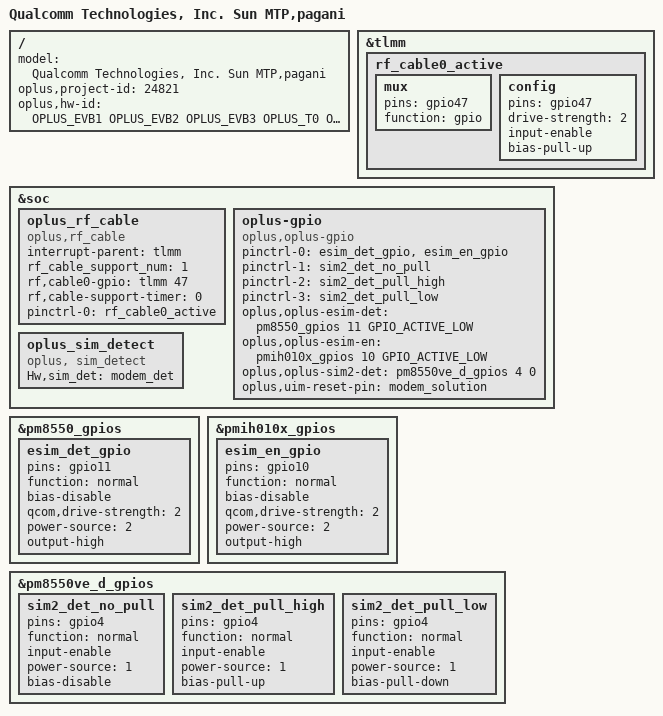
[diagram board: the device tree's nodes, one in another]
/dts-v1/;
/plugin/;
#include <dt-bindings/oplus/hw-id.h>
#include "../qcom/sun-mtp-v8-overlay.dts"
#include "sun_overlay_common.dtsi"
#include "oplus_nfc/pagani_nfc.dtsi"
#include "pagani_overlay_common.dtsi"
#include "oplus_misc/oplus-misc-24821.dtsi"
#include "oplus_uff/oplus-uff-24821.dtsi"
#include "tp/pagani-oplus-tp-24821.dtsi"
#include "oplus_chg/oplus-chg-24821.dtsi"
#include "sensor/pagani-sensor-24821-24875.dtsi"
#include "mm/pagani-24821-sun-mm.dtsi"

/ {
    model = "Qualcomm Technologies, Inc. Sun MTP,pagani";

    oplus,project-id = <24821>;
    oplus,hw-id = <OPLUS_EVB1 OPLUS_EVB2 OPLUS_EVB3 OPLUS_T0 OPLUS_T1 OPLUS_EVT1 OPLUS_EVT2 OPLUS_DVT1 OPLUS_DVT2 OPLUS_PVT1>;
};

&tlmm {
    //#ifdef OPLUS_FEATURE_RF_CABLE_DETECT
    rf_cable0_active: rf_cable0_active {
        mux {
            pins = "gpio47";
            function = "gpio";
        };
        config {
            pins = "gpio47";
            drive-strength = <2>;
            input-enable;
            bias-pull-up;
        };
    };
    //#endif /* OPLUS_FEATURE_RF_CABLE_DETECT */
};

&soc {
    //#ifdef OPLUS_FEATURE_RF_CABLE_DETECT
    oplus_rf_cable {
        compatible = "oplus,rf_cable";
        interrupt-parent = <&tlmm>;
        rf_cable_support_num = <1>;
        rf,cable0-gpio = <&tlmm 47 0>;
        rf,cable-support-timer = <0>;
        pinctrl-names = "rf_cable_active";
        pinctrl-0 = <&rf_cable0_active>;
    };
    //#endif /* OPLUS_FEATURE_RF_CABLE_DETECT */
    //#ifdef OPLUS_FEATURE_ESIM
    oplus-gpio {
        compatible = "oplus,oplus-gpio";
        pinctrl-names = "oplus_esim", "sim2_det_no_pull", "sim2_det_pull_high", "sim2_det_pull_low";
        pinctrl-0 = <&esim_det_gpio &esim_en_gpio>;
        pinctrl-1 = <&sim2_det_no_pull>;
        pinctrl-2 = <&sim2_det_pull_high>;
        pinctrl-3 = <&sim2_det_pull_low>;
        oplus,oplus-esim-det = <&pm8550_gpios 11 GPIO_ACTIVE_LOW>;
        oplus,oplus-esim-en = <&pmih010x_gpios 10 GPIO_ACTIVE_LOW>;
        oplus,oplus-sim2-det = <&pm8550ve_d_gpios 4 0>;
        oplus,uim-reset-pin = "modem_solution";
    };
    oplus_sim_detect {
        compatible = "oplus, sim_detect";
        Hw,sim_det = "modem_det";
    };
    //#endif /*OPLUS_FEATURE_ESIM*/
};

&pm8550_gpios {
  esim_det_gpio: esim_det_gpio {
      pins = "gpio11";
      function = "normal";
      bias-disable; /* NO pull */
      qcom,drive-strength = <2>; /* 2 MA */
      power-source = <2>; /* 1.2V */
      output-high;
  };
};

&pmih010x_gpios {
  esim_en_gpio: esim_en_gpio {
      pins = "gpio10";
      function = "normal";
      bias-disable; /* NO pull */
      qcom,drive-strength = <2>; /* 2 MA */
      power-source = <2>; /* 1.2V */
      output-high;
  };
};

&pm8550ve_d_gpios {
    sim2_det_no_pull: sim2_det_no_pull {
        pins = "gpio4";
        function = "normal";
        input-enable;
        power-source = <1>;
        bias-disable;
    };

    sim2_det_pull_high: sim2_det_pull_high {
        pins = "gpio4";
        function = "normal";
        input-enable;
        power-source = <1>;
        bias-pull-up;
    };

    sim2_det_pull_low: sim2_det_pull_low {
        pins = "gpio4";
        function = "normal";
        input-enable;
        power-source = <1>;
        bias-pull-down;
    };
};
